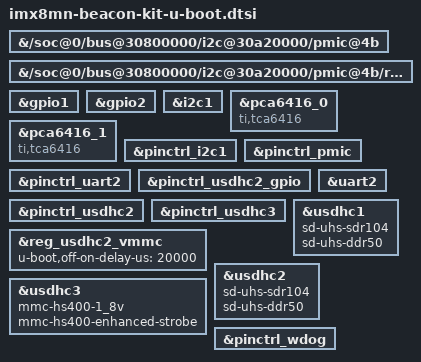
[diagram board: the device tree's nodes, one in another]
// SPDX-License-Identifier: GPL-2.0+
/*
 * Copyright 2022 Logic PD, Inc. dba Beacon EmbeddedWorks
 */

#include "imx8mn-u-boot.dtsi"

&{/soc@0/bus@30800000/i2c@30a20000/pmic@4b} {
	bootph-pre-ram;
};

&{/soc@0/bus@30800000/i2c@30a20000/pmic@4b/regulators} {
	bootph-pre-ram;
};

&gpio1 {
	bootph-pre-ram;
};

&gpio2 {
	bootph-pre-ram;
};

&i2c1 {
	bootph-pre-ram;
};

&pca6416_0 {
	compatible = "ti,tca6416";
};

&pca6416_1 {
	compatible = "ti,tca6416";
};

&pinctrl_i2c1 {
	bootph-pre-ram;
};

&pinctrl_pmic {
	bootph-pre-ram;
};

&pinctrl_uart2 {
	bootph-pre-ram;
};

&pinctrl_usdhc2_gpio {
	bootph-pre-ram;
};

&pinctrl_usdhc2 {
	bootph-pre-ram;
};

&pinctrl_usdhc3 {
	bootph-pre-ram;
};

&reg_usdhc2_vmmc {
	u-boot,off-on-delay-us = <20000>;
};

&uart2 {
	bootph-pre-ram;
};

&usdhc1 {
	bootph-pre-ram;
	sd-uhs-sdr104;
	sd-uhs-ddr50;
};

&usdhc2 {
	bootph-pre-ram;
	sd-uhs-sdr104;
	sd-uhs-ddr50;
};

&usdhc3 {
	bootph-pre-ram;
	mmc-hs400-1_8v;
	mmc-hs400-enhanced-strobe;
};

&pinctrl_wdog {
	bootph-pre-ram;
};
